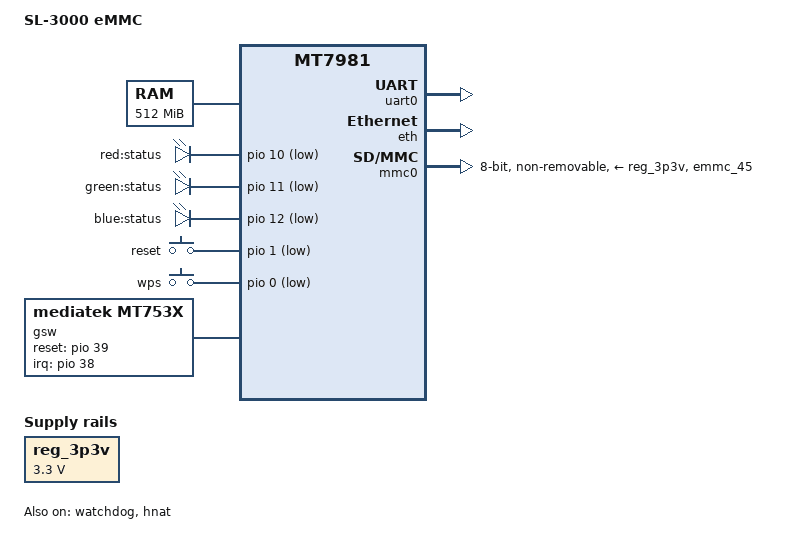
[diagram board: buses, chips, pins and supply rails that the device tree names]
/dts-v1/;
#include "mt7981.dtsi"

/ {
	model = "SL-3000 eMMC";
	compatible = "sl,3000-emmc", "mediatek,mt7981";

	chosen {
		bootargs = "console=ttyS0,115200n1 loglevel=8 \
			    earlycon=uart8250,mmio32,0x11002000 \
			    root=PARTLABEL=rootfs rootwait rootfstype=squashfs,f2fs";
	};

	aliases {
		led-boot = &rgb_red;
		led-failsafe = &rgb_red;
		led-running = &rgb_green;
		led-upgrade = &rgb_blue;
	};

	memory {
		reg = <0 0x40000000 0 0x20000000>;
	};

	reg_3p3v: regulator-3p3v {
		compatible = "regulator-fixed";
		regulator-name = "fixed-3.3V";
		regulator-min-microvolt = <3300000>;
		regulator-max-microvolt = <3300000>;
		regulator-boot-on;
		regulator-always-on;
	};

	leds {
		compatible = "gpio-leds";

		rgb_red: led-0 {
			label = "red:status";
			gpios = <&pio 10 GPIO_ACTIVE_LOW>;
		};

		rgb_green: led-1 {
			label = "green:status";
			gpios = <&pio 11 GPIO_ACTIVE_LOW>;
		};

		rgb_blue: led-2 {
			label = "blue:status";
			gpios = <&pio 12 GPIO_ACTIVE_LOW>;
		};
	};

	gpio-keys {
		compatible = "gpio-keys";

		reset {
			label = "reset";
			linux,code = <KEY_RESTART>;
			gpios = <&pio 1 GPIO_ACTIVE_LOW>;
		};

		wps {
			label = "wps";
			gpios = <&pio 0 GPIO_ACTIVE_LOW>;
			linux,code = <BTN_9>;
			linux,input-type = <EV_SW>;
		};
	};

	gsw: gsw@0 {
		compatible = "mediatek,mt753x";
		mediatek,ethsys = <&ethsys>;
		#address-cells = <1>;
		#size-cells = <0>;
	};
};

&uart0 {
	status = "okay";
};

&watchdog {
	status = "okay";
};

&eth {
	status = "okay";

	gmac0: mac@0 {
		compatible = "mediatek,eth-mac";
		reg = <0>;
		phy-mode = "2500base-x";

		fixed-link {
			speed = <2500>;
			full-duplex;
			pause;
		};
	};

	mdio: mdio-bus {
		#address-cells = <1>;
		#size-cells = <0>;
	};
};

&gsw {
	mediatek,mdio = <&mdio>;
	mediatek,portmap = "llllw";
	mediatek,mdio_master_pinmux = <0>;
	reset-gpios = <&pio 39 0>;
	interrupt-parent = <&pio>;
	interrupts = <38 IRQ_TYPE_LEVEL_HIGH>;
	status = "okay";

	port6: port@6 {
		compatible = "mediatek,mt753x-port";
		mediatek,ssc-on;
		reg = <6>;
		phy-mode = "sgmii";

		fixed-link {
			speed = <2500>;
			full-duplex;
		};
	};
};

&hnat {
	mtketh-wan = "eth0.2";
	mtketh-ppd = "eth0.1";
	mtketh-lan = "eth0";
	mtketh-max-gmac = <1>;
	status = "okay";
};

&mmc0 {
	bus-width = <8>;
	cap-mmc-highspeed;
	max-frequency = <52000000>;
	no-sd;
	no-sdio;
	non-removable;
	pinctrl-names = "default", "state_uhs";
	pinctrl-0 = <&mmc0_pins_default>;
	pinctrl-1 = <&mmc0_pins_uhs>;
	vmmc-supply = <&reg_3p3v>;
	non-removable;
	status = "okay";
};

&pio {
	mmc0_pins_default: mmc0-pins-default {
		mux {
			function = "flash";
			groups = "emmc_45";
		};
	};

	mmc0_pins_uhs: mmc0-pins-uhs {
		mux {
			function = "flash";
			groups = "emmc_45";
		};
	};
};
